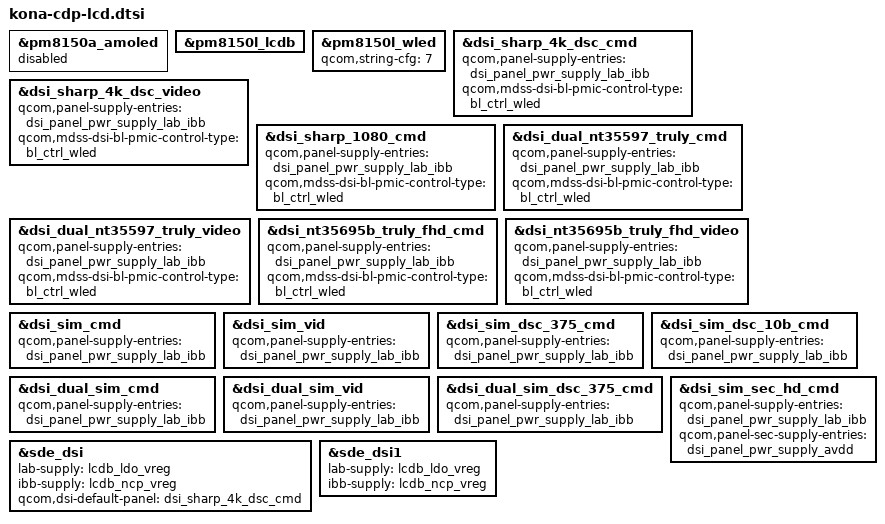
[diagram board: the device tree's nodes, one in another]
#include "kona-cdp.dtsi"

&pm8150a_amoled {
	status = "disabled";
};

&pm8150l_lcdb {
	status = "ok";
};

&pm8150l_wled {
	qcom,string-cfg = <7>;
	status = "ok";
};

&dsi_sharp_4k_dsc_cmd {
	qcom,panel-supply-entries = <&dsi_panel_pwr_supply_lab_ibb>;
	qcom,mdss-dsi-bl-pmic-control-type = "bl_ctrl_wled";
	/delete-property/ qcom,platform-en-gpio;
};

&dsi_sharp_4k_dsc_video {
	qcom,panel-supply-entries = <&dsi_panel_pwr_supply_lab_ibb>;
	qcom,mdss-dsi-bl-pmic-control-type = "bl_ctrl_wled";
	/delete-property/ qcom,platform-en-gpio;
};

&dsi_sharp_1080_cmd {
	qcom,panel-supply-entries = <&dsi_panel_pwr_supply_lab_ibb>;
	qcom,mdss-dsi-bl-pmic-control-type = "bl_ctrl_wled";
};

&dsi_dual_nt35597_truly_cmd {
	qcom,panel-supply-entries = <&dsi_panel_pwr_supply_lab_ibb>;
	qcom,mdss-dsi-bl-pmic-control-type = "bl_ctrl_wled";
};

&dsi_dual_nt35597_truly_video {
	qcom,panel-supply-entries = <&dsi_panel_pwr_supply_lab_ibb>;
	qcom,mdss-dsi-bl-pmic-control-type = "bl_ctrl_wled";
};

&dsi_nt35695b_truly_fhd_cmd {
	qcom,panel-supply-entries = <&dsi_panel_pwr_supply_lab_ibb>;
	qcom,mdss-dsi-bl-pmic-control-type = "bl_ctrl_wled";
};

&dsi_nt35695b_truly_fhd_video {
	qcom,panel-supply-entries = <&dsi_panel_pwr_supply_lab_ibb>;
	qcom,mdss-dsi-bl-pmic-control-type = "bl_ctrl_wled";
};

&dsi_sim_cmd {
	qcom,panel-supply-entries = <&dsi_panel_pwr_supply_lab_ibb>;
};

&dsi_sim_vid {
	qcom,panel-supply-entries = <&dsi_panel_pwr_supply_lab_ibb>;
};

&dsi_sim_dsc_375_cmd {
	qcom,panel-supply-entries = <&dsi_panel_pwr_supply_lab_ibb>;
};

&dsi_sim_dsc_10b_cmd {
	qcom,panel-supply-entries = <&dsi_panel_pwr_supply_lab_ibb>;
};

&dsi_dual_sim_cmd {
	qcom,panel-supply-entries = <&dsi_panel_pwr_supply_lab_ibb>;
};

&dsi_dual_sim_vid {
	qcom,panel-supply-entries = <&dsi_panel_pwr_supply_lab_ibb>;
};

&dsi_dual_sim_dsc_375_cmd {
	qcom,panel-supply-entries = <&dsi_panel_pwr_supply_lab_ibb>;
};

&dsi_sim_sec_hd_cmd {
	qcom,panel-supply-entries = <&dsi_panel_pwr_supply_lab_ibb>;
	qcom,panel-sec-supply-entries = <&dsi_panel_pwr_supply_avdd>;
};

&sde_dsi {
	/delete-property/ avdd-supply;
	lab-supply = <&lcdb_ldo_vreg>;
	ibb-supply = <&lcdb_ncp_vreg>;
	qcom,dsi-default-panel = <&dsi_sharp_4k_dsc_cmd>;
};

&sde_dsi1 {
	lab-supply = <&lcdb_ldo_vreg>;
	ibb-supply = <&lcdb_ncp_vreg>;
};
